# RZ/A1H register map
Vendor: Renesas
Registers are 32-bit, read-write, reset 0x0 unless marked. A register's access mark holds for its fields unless they carry their own. Offsets are from the block's base; [hi:lo] are bit positions; {n}, {i} and the like mark numbered series.

## L2C
Base 0x3FFFF000
0x00 REG0_CACHE_ID
0x04 REG0_CACHE_TYPE
0x100 REG1_CONTROL
0x104 REG1_AUX_CONTROL
0x108 REG1_TAG_RAM_CONTROL
0x10C REG1_DATA_RAM_CONTROL
0x200 REG2_EV_COUNTER_CTRL
0x204 REG2_EV_COUNTER1_CFG
0x208 REG2_EV_COUNTER0_CFG
0x20C REG2_EV_COUNTER1
0x210 REG2_EV_COUNTER0
0x214 REG2_INT_MASK
0x218 REG2_INT_MASK_STATUS
0x21C REG2_INT_RAW_STATUS
0x220 REG2_INT_CLEAR
0x730 REG7_CACHE_SYNC
0x770 REG7_INV_PA
0x77C REG7_INV_WAY
0x7B0 REG7_CLEAN_PA
0x7B8 REG7_CLEAN_INDEX
0x7BC REG7_CLEAN_WAY
0x7F0 REG7_CLEAN_INV_PA
0x7F8 REG7_CLEAN_INV_INDEX
0x7FC REG7_CLEAN_INV_WAY
{0x900+8i} REG9_D_LOCKDOWN{i} (i=0..7)
{0x904+8i} REG9_I_LOCKDOWN{i} (i=0..7)
0x950 REG9_LOCK_LINE_EN
0x954 REG9_UNLOCK_WAY
0xC00 REG12_ADDR_FILTERING_START
0xC04 REG12_ADDR_FILTERING_END
0xF40 REG15_DEBUG_CTRL
0xF60 REG15_PREFETCH_CTRL
0xF80 REG15_POWER_CTRL

## LIN0
Base 0xFCFE9000
Same registers: LIN1 0xFCFE9800
0x01 LWBR 8-bit — RLN3nLWBR
0x02 LBRP0 8-bit — RLN3nLBRP0
0x03 LBRP1 8-bit — RLN3nLBRP1
0x04 LSTC 8-bit — RLN3nLSTC
0x08 LMD 8-bit — RLN3nLMD
0x09 LBFC 8-bit — RLN3nLBFC
0x0A LSC 8-bit — RLN3nLSC
0x0B LWUP 8-bit — RLN3nLWUP
0x0C LIE 8-bit — RLN3nLIE
0x0D LEDE 8-bit — RLN3nLEDE
0x0E LCUC 8-bit — RLN3nLCUC
0x10 LTRC 8-bit — RLN3nLTRC
0x11 LMST 8-bit — RLN3nLMST
0x12 LST 8-bit — RLN3nLST
0x13 LEST 8-bit — RLN3nLEST
0x14 LDFC 8-bit — RLN3nLDFC
0x15 LIDB 8-bit — RLN3nLIDB
0x16 LCBR 8-bit — RLN3nLCBR
{0x17+i} LDBR{i} 8-bit (i=1..8) — RLN3nLDBR{i}

## LVDS
Base 0xFCFF7A30
0x00 UPDATE — LVDS_UPDATE
0x04 FCL — LVDSFCL
0x20 LCLKSELR
0x24 LPLLSETR
0x2C LPHYACC

## MLB
Base 0xE8034000
0x00 DCCR
0x04 SSCR
0x08 SDCR
0x0C SMCR
0x1C VCCR
0x20 SBCR
0x24 ABCR
0x28 CBCR
0x2C IBCR
0x30 CICR
{0x40+0x10*i} CECR{i} (i=0..30)
{0x44+0x10*i} CSCR{i} (i=0..30)
{0x48+0x10*i} CCBCR{i} (i=0..30)
{0x4C+0x10*i} CNBCR{i} (i=0..30)
{0x280+4i} LCBCR{i} (i=0..30)

## MMC
Base 0xE804C800
0x00 CE_CMD_SETH 16-bit
0x02 CE_CMD_SETL 16-bit
0x08 CE_ARG
0x0C CE_ARG_CMD12
0x10 CE_CMD_CTRL
0x14 CE_BLOCK_SET
0x18 CE_CLK_CTRL
0x1C CE_BUF_ACC
0x20 CE_RESP3
0x24 CE_RESP2
0x28 CE_RESP1
0x2C CE_RESP0
0x30 CE_RESP_CMD12
0x34 CE_DATA
0x40 CE_INT
0x44 CE_INT_EN
0x48 CE_HOST_STS1
0x4C CE_HOST_STS2
0x5C CE_DMA_MODE
0x70 CE_DETECT
0x74 CE_ADD_MODE
0x7C CE_VERSION

## MTU2
Base 0xFCFF0000
0x00 TCR_2 8-bit
0x01 TMDR_2 8-bit
0x02 TIOR_2 8-bit
0x04 TIER_2 8-bit
0x05 TSR_2 8-bit
0x06 TCNT_2 16-bit
0x08 TGRA_2 16-bit
0x0A TGRB_2 16-bit
0x200 TCR_3 8-bit
0x201 TCR_4 8-bit
0x202 TMDR_3 8-bit
0x203 TMDR_4 8-bit
0x204 TIORH_3 8-bit
0x205 TIORL_3 8-bit
0x206 TIORH_4 8-bit
0x207 TIORL_4 8-bit
0x208 TIER_3 8-bit
0x209 TIER_4 8-bit
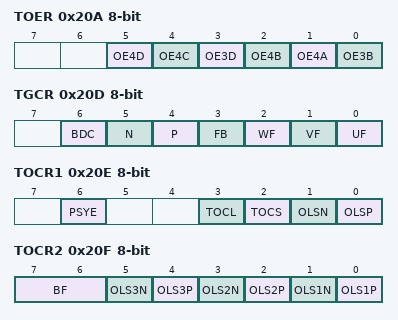
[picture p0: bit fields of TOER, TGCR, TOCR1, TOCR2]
0x20A TOER 8-bit
  [5] OE4D, [4] OE4C, [3] OE3D, [2] OE4B, [1] OE4A, [0] OE3B
0x20D TGCR 8-bit
  [6] BDC, [5] N, [4] P, [3] FB, [2] WF, [1] VF, [0] UF
0x20E TOCR1 8-bit
  [6] PSYE, [3] TOCL, [2] TOCS, [1] OLSN, [0] OLSP
0x20F TOCR2 8-bit
  [7:6] BF, [5] OLS3N, [4] OLS3P, [3] OLS2N, [2] OLS2P, [1] OLS1N, [0] OLS1P
0x210 TCNT_3 16-bit
0x212 TCNT_4 16-bit
0x214 TCDR 16-bit
  [15:0] D
0x216 TDDR 16-bit
  [15:0] D
0x218 TGRA_3 16-bit
0x21A TGRB_3 16-bit
0x21C TGRA_4 16-bit
0x21E TGRB_4 16-bit
0x220 TCNTS 16-bit
  [15:0] D
0x222 TCBR 16-bit
  [15:0] D
0x224 TGRC_3 16-bit
0x226 TGRD_3 16-bit
0x228 TGRC_4 16-bit
0x22A TGRD_4 16-bit
0x22C TSR_3 8-bit
0x22D TSR_4 8-bit
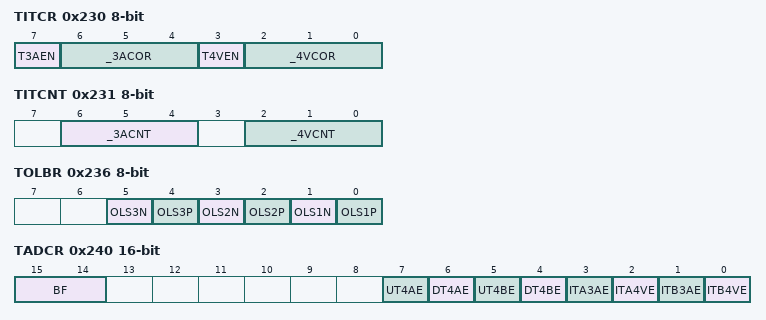
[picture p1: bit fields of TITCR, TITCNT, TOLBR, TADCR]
0x230 TITCR 8-bit
  [7] T3AEN, [6:4] _3ACOR, [3] T4VEN, [2:0] _4VCOR
0x231 TITCNT 8-bit
  [6:4] _3ACNT, [2:0] _4VCNT
0x232 TBTER 8-bit
  [1:0] BTE
0x234 TDER 8-bit
  [0] TDER
0x236 TOLBR 8-bit
  [5] OLS3N, [4] OLS3P, [3] OLS2N, [2] OLS2P, [1] OLS1N, [0] OLS1P
0x238 TBTM_3 8-bit
0x239 TBTM_4 8-bit
0x240 TADCR 16-bit
  [15:14] BF, [7] UT4AE, [6] DT4AE, [5] UT4BE, [4] DT4BE, [3] ITA3AE, [2] ITA4VE, [1] ITB3AE, [0] ITB4VE
0x244 TADCORA_4 16-bit
0x246 TADCORB_4 16-bit
0x248 TADCOBRA_4 16-bit
0x24A TADCOBRB_4 16-bit
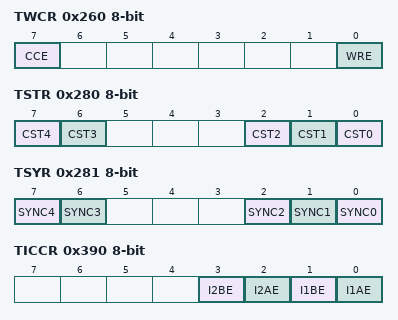
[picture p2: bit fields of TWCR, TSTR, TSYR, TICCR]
0x260 TWCR 8-bit
  [7] CCE, [0] WRE
0x280 TSTR 8-bit
  [7] CST4, [6] CST3, [2] CST2, [1] CST1, [0] CST0
0x281 TSYR 8-bit
  [7] SYNC4, [6] SYNC3, [2] SYNC2, [1] SYNC1, [0] SYNC0
0x284 TRWER 8-bit
  [0] RWE
0x300 TCR_0 8-bit
0x301 TMDR_0 8-bit
0x302 TIORH_0 8-bit
0x303 TIORL_0 8-bit
0x304 TIER_0 8-bit
0x305 TSR_0 8-bit
0x306 TCNT_0 16-bit
0x308 TGRA_0 16-bit
0x30A TGRB_0 16-bit
0x30C TGRC_0 16-bit
0x30E TGRD_0 16-bit
0x320 TGRE_0 16-bit
0x322 TGRF_0 16-bit
0x324 TIER2_0 8-bit
0x325 TSR2_0 8-bit
0x326 TBTM_0 8-bit
0x380 TCR_1 8-bit
0x381 TMDR_1 8-bit
0x382 TIOR_1 8-bit
0x384 TIER_1 8-bit
0x385 TSR_1 8-bit
0x386 TCNT_1 16-bit
0x388 TGRA_1 16-bit
0x38A TGRB_1 16-bit
0x390 TICCR 8-bit
  [3] I2BE, [2] I2AE, [1] I1BE, [0] I1AE
